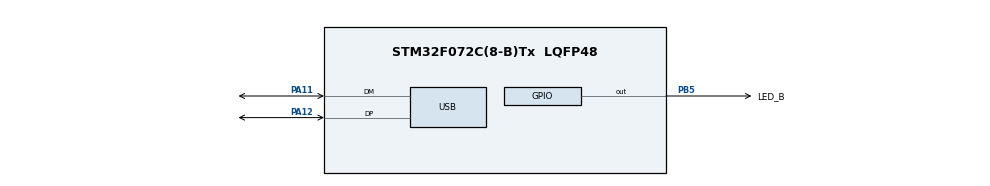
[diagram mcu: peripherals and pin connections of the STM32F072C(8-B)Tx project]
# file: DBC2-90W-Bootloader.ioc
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Mcu.Family=STM32F0
Mcu.Name=STM32F072C(8-B)Tx
Mcu.Package=LQFP48
NVIC.USB_IRQn=true\:0\:0\:false\:false\:true\:false\:true\:true
PA11.Mode=Device
PA11.Signal=USB_DM
PA12.Mode=Device
PA12.Signal=USB_DP
PB5.GPIO_Label=LED_B
PB5.Signal=GPIO_Output
ProjectManager.HeapSize=0x200
ProjectManager.StackSize=0x400
ProjectManager.TargetToolchain=STM32CubeIDE
RCC.AHBFreq_Value=48000000
RCC.APB1Freq_Value=48000000
RCC.APB1TimFreq_Value=48000000
RCC.HCLKFreq_Value=48000000
RCC.SYSCLKFreq_VALUE=48000000
RCC.SYSCLKSource=RCC_SYSCLKSOURCE_HSI48
USB_DEVICE.APP_RX_DATA_SIZE=1024
USB_DEVICE.APP_TX_DATA_SIZE=1024
USB_DEVICE.CLASS_NAME_FS=CDC
USB_DEVICE.MANUFACTURER_STRING=ENKO Control Systems
USB_DEVICE.USBD_DEBUG_LEVEL=0
USB_DEVICE.USBD_MAX_STR_DESC_SIZ=512
USB_DEVICE.VirtualMode=Cdc
USB_DEVICE.VirtualModeFS=Cdc_FS
VP_USB_DEVICE_VS_USB_DEVICE_CDC_FS.Mode=CDC_FS
board=custom

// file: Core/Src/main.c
/* USER CODE BEGIN Header */
/**
  ******************************************************************************
  * @file           : main.c
  * @brief          : Main program body
  ******************************************************************************
  * @attention
  *
  * Copyright (c) 2022 STMicroelectronics.
  * All rights reserved.
  *
  * This software is licensed under terms that can be found in the LICENSE file
  * in the root directory of this software component.
  * If no LICENSE file comes with this software, it is provided AS-IS.
  *
  ******************************************************************************
  */
/* USER CODE END Header */
#include "main.h"

/* USER CODE BEGIN Includes */
#include "bootloader.h"
/* USER CODE END Includes */

void SystemClock_Config(void);
static void MX_GPIO_Init(void);

int main(void)
{

  /* MCU Configuration--------------------------------------------------------*/

  /* Reset of all peripherals, Initializes the Flash interface and the Systick. */
  HAL_Init();

  /* Configure the system clock */
  SystemClock_Config();

  /* Initialize all configured peripherals */
  MX_GPIO_Init();
  /* USER CODE BEGIN 2 */
  BOOTLOADER_Init();
  /* USER CODE END 2 */

  /* Infinite loop */
  while (1)
  {

  }
}

void SystemClock_Config(void)
{
  LL_FLASH_SetLatency(LL_FLASH_LATENCY_1);
  while(LL_FLASH_GetLatency() != LL_FLASH_LATENCY_1)
  {
  }
  LL_RCC_HSI48_Enable();

   /* Wait till HSI48 is ready */
  while(LL_RCC_HSI48_IsReady() != 1)
  {

  }
  LL_RCC_SetAHBPrescaler(LL_RCC_SYSCLK_DIV_1);
  LL_RCC_SetAPB1Prescaler(LL_RCC_APB1_DIV_1);
  LL_RCC_SetSysClkSource(LL_RCC_SYS_CLKSOURCE_HSI48);

   /* Wait till System clock is ready */
  while(LL_RCC_GetSysClkSource() != LL_RCC_SYS_CLKSOURCE_STATUS_HSI48)
  {

  }
  LL_SetSystemCoreClock(48000000);

   /* Update the time base */
  if (HAL_InitTick (TICK_INT_PRIORITY) != HAL_OK)
  {
    Error_Handler();
  }
  LL_RCC_SetUSBClockSource(LL_RCC_USB_CLKSOURCE_HSI48);
}

static void MX_GPIO_Init(void)
{
  LL_GPIO_InitTypeDef GPIO_InitStruct = {0};

  /* GPIO Ports Clock Enable */
  LL_AHB1_GRP1_EnableClock(LL_AHB1_GRP1_PERIPH_GPIOA);
  LL_AHB1_GRP1_EnableClock(LL_AHB1_GRP1_PERIPH_GPIOB);

  /**/
  LL_GPIO_ResetOutputPin(LED_B_GPIO_Port, LED_B_Pin);

  /**/
  GPIO_InitStruct.Pin = LED_B_Pin;
  GPIO_InitStruct.Mode = LL_GPIO_MODE_OUTPUT;
  GPIO_InitStruct.Speed = LL_GPIO_SPEED_FREQ_LOW;
  GPIO_InitStruct.OutputType = LL_GPIO_OUTPUT_PUSHPULL;
  GPIO_InitStruct.Pull = LL_GPIO_PULL_NO;
  LL_GPIO_Init(LED_B_GPIO_Port, &GPIO_InitStruct);

}

void Error_Handler(void)
{
  __disable_irq();
  while (1)
  {
  }
}
